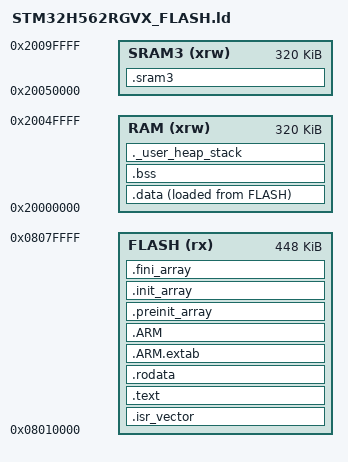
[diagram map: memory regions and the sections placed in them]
/*
 ******************************************************************************
 **
 ** @file        : LinkerScript.ld
 **
 ** @author      : Auto-generated by STM32CubeIDE
 **
 ** @brief       : Linker script for STM32H562xx Device from STM32H5 series
 **                      2048Kbytes FLASH
 **                      640Kbytes RAM
 **
 **                Set heap size, stack size and stack location according
 **                to application requirements.
 **
 **                Set memory bank area and size if external memory is used
 **
 **  Target      : STMicroelectronics STM32
 **
 **  Distribution: The file is distributed as is, without any warranty
 **                of any kind.
 **
 ******************************************************************************
 ** @attention
 **
 ** Copyright (c) 2023 STMicroelectronics.
 ** All rights reserved.
 **
 ** This software is licensed under terms that can be found in the LICENSE file
 ** in the root directory of this software component.
 ** If no LICENSE file comes with this software, it is provided AS-IS.
 **
 ******************************************************************************
 */

/* Entry Point */
ENTRY(Reset_Handler)

/* Highest address of the user mode stack */
_estack = ORIGIN(RAM) + LENGTH(RAM); /* end of "RAM" Ram type memory */
_sstack = _estack - _Min_Stack_Size;

_Min_Heap_Size = 0x200; /* required amount of heap */
_Min_Stack_Size = 0x2000; /* required amount of stack(KOGUMA MK4: 8KB。迷路の計算に使う) */

/* Memories definition */
MEMORY
{
  /* KOGUMA MK4(2026-11-28): ふつうの変数とスタックは SRAM1・SRAM2(320KB)、ログは SRAM3(320KB。下の .sram3)。
   * プログラムは 0x08010000 から 448KB(先頭の 64KB はブートローダ。software/bootloader/README.md)。
   * 後ろの 512KB(バンク 2)はパラメータ・迷路・ログの保存に使う(drv/flash_memory.c) */
  RAM    (xrw)    : ORIGIN = 0x20000000,   LENGTH = 320K
  SRAM3  (xrw)    : ORIGIN = 0x20050000,   LENGTH = 320K
  FLASH    (rx)    : ORIGIN = 0x8010000,   LENGTH = 448K
}

/* Sections */
SECTIONS
{
  /* The startup code into "FLASH" Rom type memory */
  .isr_vector :
  {
    . = ALIGN(4);
    KEEP(*(.isr_vector)) /* Startup code */
    . = ALIGN(4);
  } >FLASH

  /* The program code and other data into "FLASH" Rom type memory */
  .text :
  {
    . = ALIGN(4);
    *(.text)           /* .text sections (code) */
    *(.text*)          /* .text* sections (code) */
    *(.glue_7)         /* glue arm to thumb code */
    *(.glue_7t)        /* glue thumb to arm code */
    *(.eh_frame)

    KEEP (*(.init))
    KEEP (*(.fini))

    . = ALIGN(4);
    _etext = .;        /* define a global symbols at end of code */
  } >FLASH

  /* Constant data into "FLASH" Rom type memory */
  .rodata :
  {
    . = ALIGN(4);
    *(.rodata)         /* .rodata sections (constants, strings, etc.) */
    *(.rodata*)        /* .rodata* sections (constants, strings, etc.) */
    . = ALIGN(4);
  } >FLASH

  .ARM.extab (READONLY) : /* The READONLY keyword is only supported in GCC11 and later, remove it if using GCC10 or earlier. */
  {
    . = ALIGN(4);
    *(.ARM.extab* .gnu.linkonce.armextab.*)
    . = ALIGN(4);
  } >FLASH

  .ARM (READONLY) : /* The READONLY keyword is only supported in GCC11 and later, remove it if using GCC10 or earlier. */
  {
    . = ALIGN(4);
    __exidx_start = .;
    *(.ARM.exidx*)
    __exidx_end = .;
    . = ALIGN(4);
  } >FLASH

  .preinit_array (READONLY) : /* The READONLY keyword is only supported in GCC11 and later, remove it if using GCC10 or earlier. */
  {
    . = ALIGN(4);
    PROVIDE_HIDDEN (__preinit_array_start = .);
    KEEP (*(.preinit_array*))
    PROVIDE_HIDDEN (__preinit_array_end = .);
    . = ALIGN(4);
  } >FLASH

  .init_array (READONLY) : /* The READONLY keyword is only supported in GCC11 and later, remove it if using GCC10 or earlier. */
  {
    . = ALIGN(4);
    PROVIDE_HIDDEN (__init_array_start = .);
    KEEP (*(SORT(.init_array.*)))
    KEEP (*(.init_array*))
    PROVIDE_HIDDEN (__init_array_end = .);
    . = ALIGN(4);
  } >FLASH

  .fini_array (READONLY) : /* The READONLY keyword is only supported in GCC11 and later, remove it if using GCC10 or earlier. */
  {
    . = ALIGN(4);
    PROVIDE_HIDDEN (__fini_array_start = .);
    KEEP (*(SORT(.fini_array.*)))
    KEEP (*(.fini_array*))
    PROVIDE_HIDDEN (__fini_array_end = .);
    . = ALIGN(4);
  } >FLASH

  /* Used by the startup to initialize data */
  _sidata = LOADADDR(.data);

  /* Initialized data sections into "RAM" Ram type memory */
  .data :
  {
    . = ALIGN(4);
    _sdata = .;        /* create a global symbol at data start */
    *(.data)           /* .data sections */
    *(.data*)          /* .data* sections */
    *(.RamFunc)        /* .RamFunc sections */
    *(.RamFunc*)       /* .RamFunc* sections */

    . = ALIGN(4);
    _edata = .;        /* define a global symbol at data end */

  } >RAM AT> FLASH

  /* Uninitialized data section into "RAM" Ram type memory */
  . = ALIGN(4);
  .bss :
  {
    /* This is used by the startup in order to initialize the .bss section */
    _sbss = .;         /* define a global symbol at bss start */
    __bss_start__ = _sbss;
    *(.bss)
    *(.bss*)
    *(COMMON)

    . = ALIGN(4);
    _ebss = .;         /* define a global symbol at bss end */
    __bss_end__ = _ebss;
  } >RAM

  /* User_heap_stack section, used to check that there is enough "RAM" Ram  type memory left */
  ._user_heap_stack :
  {
    . = ALIGN(8);
    PROVIDE ( end = . );
    PROVIDE ( _end = . );
    . = . + _Min_Heap_Size;
    . = . + _Min_Stack_Size;
    . = ALIGN(8);
  } >RAM

  /* KOGUMA MK4: ログなどの大きい配列(SRAM3_DATA を付けたもの。App/config/memory_place.h)。
   * NOLOAD なので、起動したときの中身は決まっていない(0 にならない)。使う前に自分で 0 にする */
  .sram3 (NOLOAD) :
  {
    . = ALIGN(4);
    *(.sram3)
    *(.sram3*)
    . = ALIGN(4);
  } >SRAM3

  /* Remove information from the compiler libraries */
  /DISCARD/ :
  {
    libc.a ( * )
    libm.a ( * )
    libgcc.a ( * )
  }

  .ARM.attributes 0 : { *(.ARM.attributes) }
}
